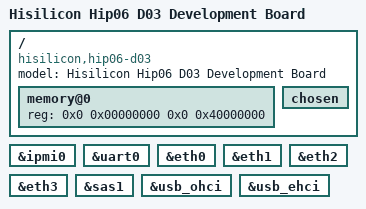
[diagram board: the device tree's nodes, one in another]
// SPDX-License-Identifier: GPL-2.0-only
/**
 * dts file for Hisilicon D03 Development Board
 *
 * Copyright (C) 2016 HiSilicon Ltd.
 */

/dts-v1/;

#include "hip06.dtsi"

/ {
	model = "Hisilicon Hip06 D03 Development Board";
	compatible = "hisilicon,hip06-d03";

	memory@0 {
		device_type = "memory";
		reg = <0x0 0x00000000 0x0 0x40000000>;
	};

	chosen { };
};

&ipmi0 {
	status = "okay";
};

&uart0 {
	status = "okay";
};

&eth0 {
	status = "okay";
};

&eth1 {
	status = "okay";
};

&eth2 {
	status = "okay";
};

&eth3 {
	status = "okay";
};

&sas1 {
	status = "okay";
};

&usb_ohci {
	status = "okay";
};

&usb_ehci {
	status = "okay";
};
